# CH585SFR register map
Vendor: WCH Ltd.; Series: CH58x; File version: 1.1
CPU: RISC-V r0p0, little endian, no MPU, no FPU, 2 interrupt priority bits
Registers are 8-bit, read-write, reset 0x0 unless marked. A register's access mark holds for its fields unless they carry their own. Offsets are from the block's base; [hi:lo] are bit positions.

## TouchKey — Touch buttons
Base 0x40001000
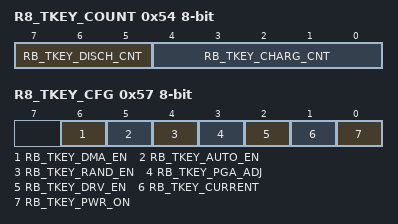
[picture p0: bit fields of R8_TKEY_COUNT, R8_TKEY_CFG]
0x54 R8_TKEY_COUNT reset not defined — RW, Touchkey charge and discharge count
  [7:5] RB_TKEY_DISCH_CNT — RW, Touchkey discharge count
  [4:0] RB_TKEY_CHARG_CNT — RW, Touchkey charge count
0x56 R8_TKEY_CONVERT — RW, Touchkey convert start control
  [0] RB_TKEY_START
0x57 R8_TKEY_CFG — RW, Touchkey configure
  [6] RB_TKEY_DMA_EN — RW, TouchKey DMA Enable
  [5] RB_TKEY_AUTO_EN — RW, TouchKey automatic trigger enable
  [4] RB_TKEY_RAND_EN — RW, TouchKey random trigger enable
  [3] RB_TKEY_PGA_ADJ — RW, ADC input PGA speed selection
  [2] RB_TKEY_DRV_EN — RW, Touchkey drive shield enable
  [1] RB_TKEY_CURRENT ro — R0, Touchkey charge current selection
  [0] RB_TKEY_PWR_ON — RW, Touchkey power on
0x7C R32_TKEY_SEL 32-bit — RW, TouchKey selection register
  [31:18] RB_TKEY_DRV_OUTEN — RW, TouchKey multi-channel driver shields each channel to enable

## ADC — Analog to Digital Converter
Base 0x40001000
0x58 R8_ADC_CHANNEL reset 0x10 — RW, ADC input channel selection
  [4:0] RB_ADC_CH_INX — RW, ADC input channel index
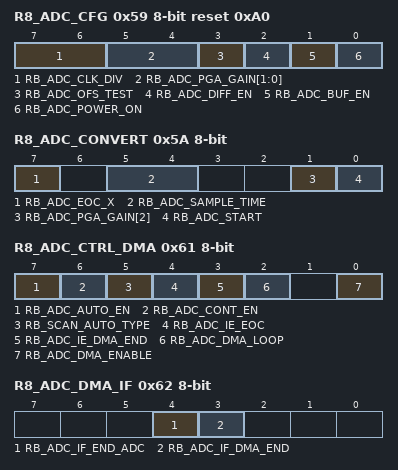
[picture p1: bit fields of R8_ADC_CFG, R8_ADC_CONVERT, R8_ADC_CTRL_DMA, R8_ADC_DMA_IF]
0x59 R8_ADC_CFG reset 0xA0 — RW, ADC configure
  [7:6] RB_ADC_CLK_DIV — RW, select ADC clock frequency: 00=3.2MHz, 01=2.67MHz, 10=5.33MHz, 11=4MHz
  [5:4] RB_ADC_PGA_GAIN[1:0] — RW, set ADC input PGA gain: 00=-12dB, 01=-6dB, 10=0dB, 11=6dB
  [3] RB_ADC_OFS_TEST — RW, enable ADC offset test mode: 0=normal mode, 1=short to test offset
  [2] RB_ADC_DIFF_EN — RW, ADC input channel mode: 0=single-end, 1=differnetial
  [1] RB_ADC_BUF_EN — RW, ADC input buffer enable
  [0] RB_ADC_POWER_ON — RW, ADC power control: 0=power down, 1=power on
0x5A R8_ADC_CONVERT — RW, ADC convert control
  [7] RB_ADC_EOC_X ro — RO, end of ADC conversion flag
  [5:4] RB_ADC_SAMPLE_TIME — RW, ADC sampling period selection
  [1] RB_ADC_PGA_GAIN[2] — RW, ADC input PGA gain direction selection, combined with RB_ ADC_ PGA_ GAIN [1:0] usage
  [0] RB_ADC_START — RW, ADC convert start control: 0=stop ADC convert, 1=start an ADC convert, auto clear
0x5B R8_TEM_SENSOR — RW, temperature sensor control
  [7] RB_TEM_SEN_PWR_ON — RW, temperature sensor power control: 0=power down, 1=power on
0x5C R16_ADC_DATA 16-bit ro reset not defined — RO, ADC data
  [11:0] RB_ADC_DATA — RO, ADC conversion data
0x5E R8_ADC_INT_FLAG ro — RO, ADC interrupt flag register
  [7] RB_ADC_IF_EOC — RO, ADC conversion interrupt flag
0x61 R8_ADC_CTRL_DMA — RW, ADC DMA control
  [7] RB_ADC_AUTO_EN — RW, enable auto continuing ADC for DMA
  [6] RB_ADC_CONT_EN — RW, enable contineous conversion ADC
  [5] RB_SCAN_AUTO_TYPE — RW, ADC SCAN mode: 1: continuous triggering 0: periodic triggering
  [4] RB_ADC_IE_EOC — RW, enable interrupt for end of ADC conversion
  [3] RB_ADC_IE_DMA_END — RW, enable interrupt for ADC DMA completion
  [2] RB_ADC_DMA_LOOP — RW, ADC DMA address loop enable
  [0] RB_ADC_DMA_ENABLE — RW, ADC DMA enable
0x62 R8_ADC_DMA_IF — RW1, ADC and DMA interrupt flag registers
  [4] RB_ADC_IF_END_ADC — interrupt flag for end of ADC conversion
  [3] RB_ADC_IF_DMA_END — interrupt flag for ADC DMA completion
0x63 R8_ADC_AUTO_CYCLE reset not defined — RO, ADC interrupt flag
  [7:0] R8_ADC_AUTO_CYCLE — auto ADC cycle value, unit is 16 Fsys
0x64 R16_ADC_DMA_NOW ro reset not defined — RO, ADC DMA current address
  [16:1] R16_ADC_DMA_NOW — ADC DMA current address
0x68 R16_ADC_DMA_BEG reset not defined — RW, ADC DMA begin address
  [16:1] R16_ADC_DMA_BEG — ADC DMA begin address
0x6C R16_ADC_DMA_END reset not defined — RW, ADC DMA end address
  [16:1] R16_ADC_DMA_END — ADC DMA end address

## TMR0 — Timer0 register
Base 0x40002000
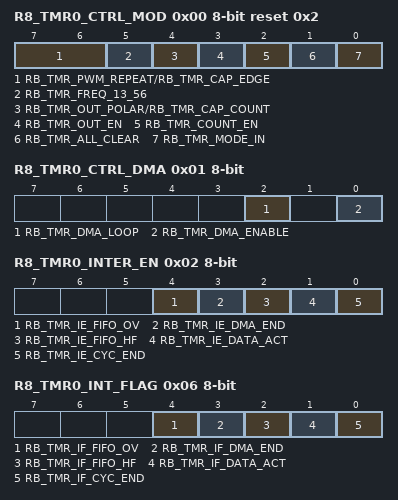
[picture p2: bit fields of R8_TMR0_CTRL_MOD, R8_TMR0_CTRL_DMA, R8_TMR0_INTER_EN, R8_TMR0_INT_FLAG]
0x00 R8_TMR0_CTRL_MOD reset 0x2 — RW, TMR0 mode control
  [7:6] RB_TMR_PWM_REPEAT/RB_TMR_CAP_EDGE — RW, timer PWM repeat mode: 00=1, 01=4, 10=8, 11-16;RW, timer capture edge mode: 00=disable, 01=edge change, 10=fall to fall, 11-rise to rise
  [5] RB_TMR_FREQ_13_56 — RW,Counting frequency setting bits for TMR0 and TMR3
  [4] RB_TMR_OUT_POLAR/RB_TMR_CAP_COUNT — RW, timer PWM output polarity: 0=default low and high action, 1=default high and low action;RW, count sub-mode if RB_TMR_MODE_IN=1: 0=capture, 1=count
  [3] RB_TMR_OUT_EN — RW, timer output enable
  [2] RB_TMR_COUNT_EN — RW, timer count enable
  [1] RB_TMR_ALL_CLEAR — RW, force clear timer FIFO and count
  [0] RB_TMR_MODE_IN — RW, timer in mode: 0=timer/PWM, 1=capture/count
0x01 R8_TMR0_CTRL_DMA — RO/WO, DMA control register
  [2] RB_TMR_DMA_LOOP — RW, Enable bit for DMA address loop function
  [0] RB_TMR_DMA_ENABLE — RW, DMA function enable bit
0x02 R8_TMR0_INTER_EN — RW, TMR0 interrupt enable
  [4] RB_TMR_IE_FIFO_OV — RW, enable interrupt for timer FIFO overflow
  [3] RB_TMR_IE_DMA_END — RW, enable interrupt for timer1/2 DMA completion
  [2] RB_TMR_IE_FIFO_HF — RW, enable interrupt for timer FIFO half (capture fifo >=4 or PWM fifo less than 3)
  [1] RB_TMR_IE_DATA_ACT — RW, enable interrupt for timer capture input action or PWM trigger
  [0] RB_TMR_IE_CYC_END — RW, enable interrupt for timer capture count timeout or PWM cycle end
0x06 R8_TMR0_INT_FLAG — RW1, TMR0 interrupt flag
  [4] RB_TMR_IF_FIFO_OV — RW1, interrupt flag for timer FIFO overflow
  [3] RB_TMR_IF_DMA_END — RW1, interrupt flag for timer1/2 DMA completion
  [2] RB_TMR_IF_FIFO_HF — RW1, interrupt flag for timer FIFO half (capture fifo >=4 or PWM fifo less than 3
  [1] RB_TMR_IF_DATA_ACT — RW1, interrupt flag for timer capture input action or PWM trigger
  [0] RB_TMR_IF_CYC_END — RW1, interrupt flag for timer capture count timeout or PWM cycle end
0x07 R8_TMR0_FIFO_COUNT ro reset not defined — RO, TMR0 FIFO count status
  [3:0] R8_TMR0_FIFO_COUNT — R0,TMR0 FIFO count status
0x08 R32_TMR0_COUNT 32-bit ro reset not defined — RO, TMR0 current count
  [25:0] R32_TMR0_COUNT — RW1,TMR0 current count
0x0C R32_TMR0_CNT_END 32-bit reset not defined — RW, TMR0 end count value, only low 26 bit
  [31:0] R32_TMR0_CNT_END — RW1,TMR0 end count value
0x10 R32_TMR0_FIFO 32-bit ro reset not defined — RO/WO, TMR0 FIFO register, only low 26 bit
  [31:0] R32_TMR0_FIFO — RW1,TMR0 FIFO register
0x14 R32_TMR0_DMA_NOW 32-bit ro reset not defined — RO, DMA current buffer address
  [16:2] RB_TMR0_DMA_NOW — RW, DMA data buffer current address
0x18 R32_TMR0_DMA_BEG 32-bit reset not defined — RW, DMA start buffer address
  [16:2] RB_TMR0_DMA_BEG — RW, The starting address of the DMA data buffer must be aligned with 4 bytes
0x1C R32_TMR0_DMA_END 32-bit reset not defined — RW, DMA end buffer address
  [16:2] RB_TMR0_DMA_END — RW, DMA data buffer end address (excluding), the address must be aligned with 4 bytes
